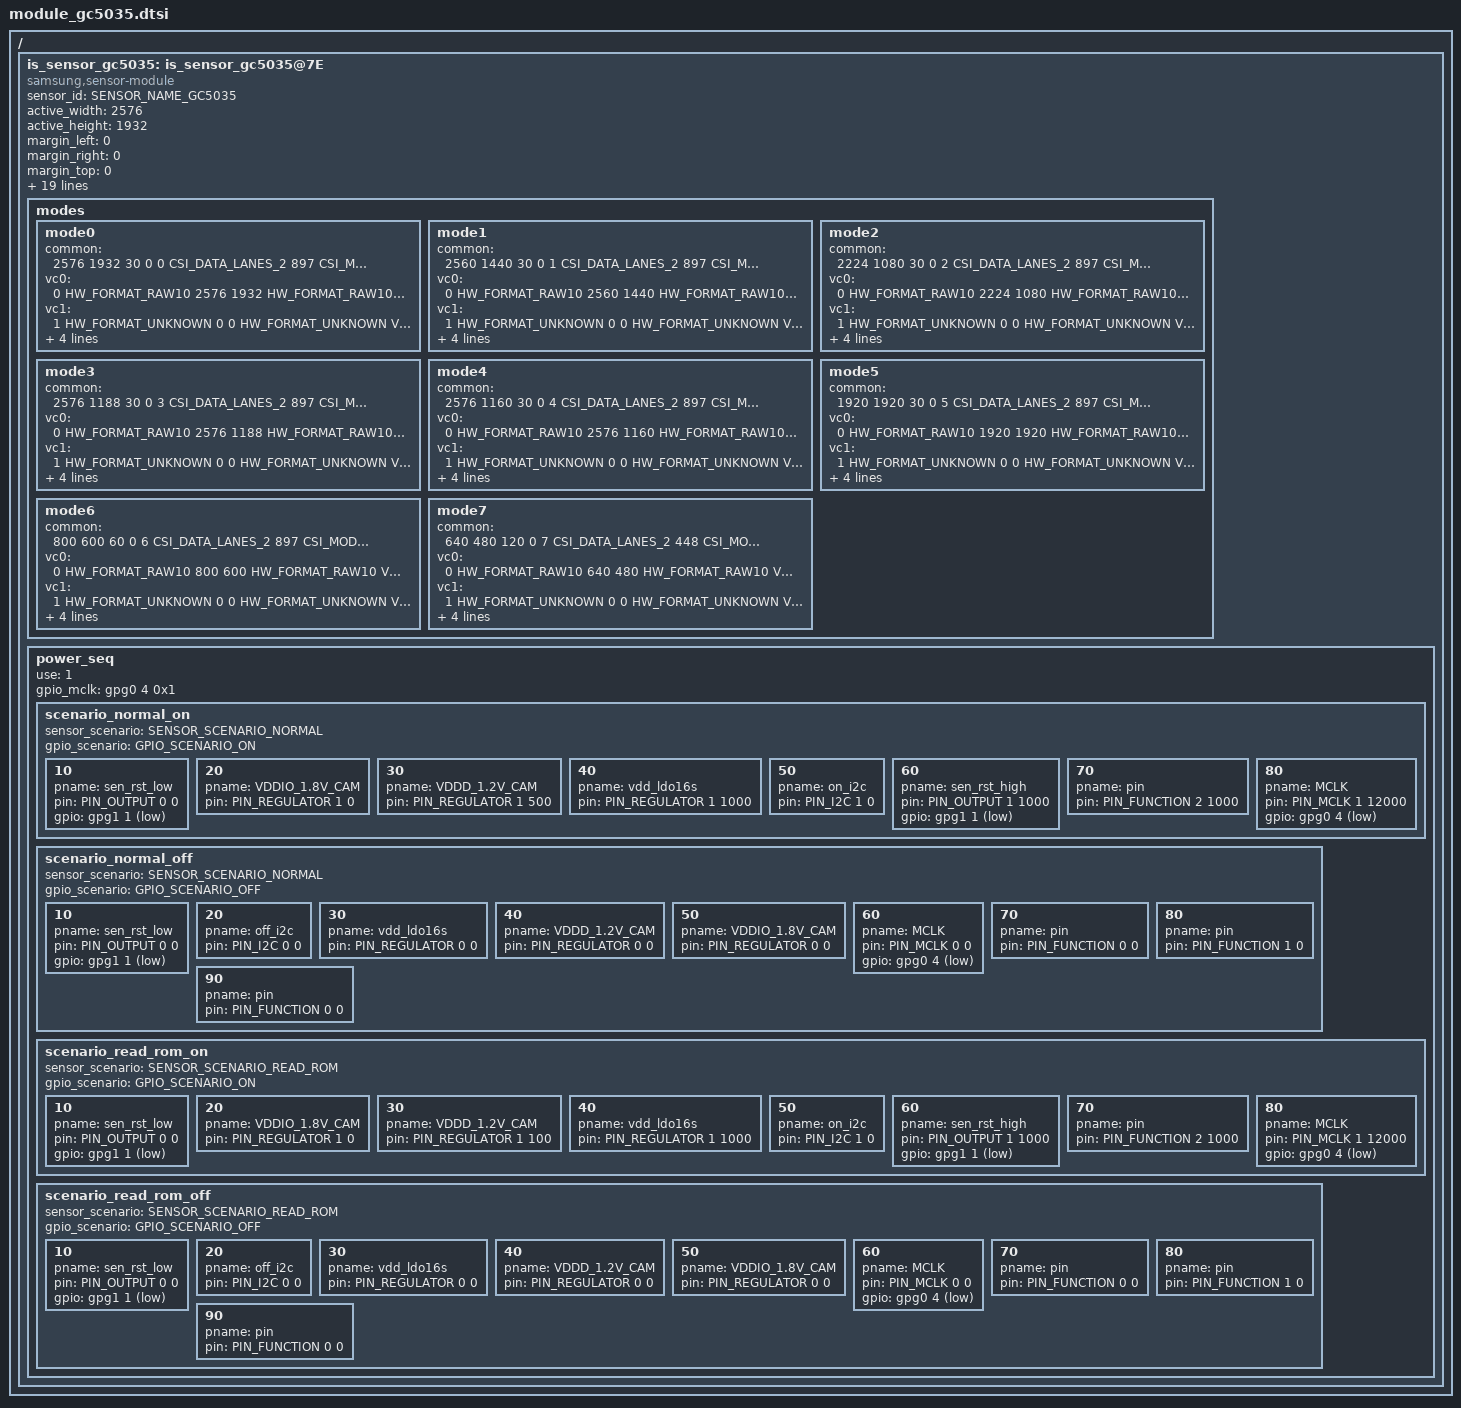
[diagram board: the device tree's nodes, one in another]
/*
 * SAMSUNG EXYNOSxxxx board camera device tree source
 *
 * Copyright (c) 2021 Samsung Electronics Co., Ltd.
 *		http://www.samsung.com
 *
 * This program is free software; you can redistribute it and/or modify
 * it under the terms of the GNU General Public License version 2 as
 * published by the Free Software Foundation.
 */

#include <dt-bindings/camera/exynos_is_dt.h>


/ {
	fragment@camera {
		target-path = "/";
		__overlay__ {
			is_sensor_gc5035: is_sensor_gc5035@7E { /* UW */
				compatible = "samsung,sensor-module";

				/* common */
				sensor_id = <SENSOR_NAME_GC5035>;
				active_width = <2576>;
				active_height = <1932>;
				margin_left = <0>;
				margin_right = <0>;
				margin_top = <0>;
				margin_bottom = <0>;
				max_framerate = <120>;
				bitwidth = <10>;
				use_retention_mode = <SENSOR_RETENTION_UNSUPPORTED>;
				sensor_maker = "GALAXYCORE";
				sensor_name = "GC5035";
				setfile_name = "setfile_gc5035.bin";

				status = "okay";

				/* board */
				pinctrl-names = "pin0", "pin1", "pin2", "release";
				pinctrl-0 = <>;
				pinctrl-1 = <&sensor_mclk2_out>;
				pinctrl-2 = <&sensor_mclk2_fn>;
				pinctrl-3 = <>;

				position = <4>; /* Rear:0. Front:1, Tele:2 */
				id = <4>; /* is_sensor id */
				mclk_ch = <2>;
				sensor_i2c_ch = <1>; /* SENSOR_CONTROL_I2C3 */

				/* vendor */
				rom_type = <3>; /* ROM_TYPE_OTPROM */
				rom_id = <4>;
				rom_cal_index = <0>;

				/*
				* Reference File : GC5035 MIPI data rate 897M official setfile V1.0.8.xlsx
				*
				*  [ 0 ] 2576 x 1932(4:3)    @30,  MIPI lane: 2, MIPI data rate(Mbps/lane):  897, Mclk(Mhz): 26
				*  [ 1 ] 2560 x 1440(16:9)   @30,  MIPI lane: 2, MIPI data rate(Mbps/lane):  897, Mclk(Mhz): 26
				*  [ 2 ] 2224 x 1080(18.5:9) @30,  MIPI lane: 2, MIPI data rate(Mbps/lane):  897, Mclk(Mhz): 26
				*  [ 3 ] 2576 x 1188(19.5:9) @30,  MIPI lane: 2, MIPI data rate(Mbps/lane):  897, Mclk(Mhz): 26
				*  [ 4 ] 2576 x 1160(20:9)   @30,  MIPI lane: 2, MIPI data rate(Mbps/lane):  897, Mclk(Mhz): 26
				*  [ 5 ] 1920 x 1920(1:1)    @30,  MIPI lane: 2, MIPI data rate(Mbps/lane):  897, Mclk(Mhz): 26
				*  [ 6 ] 1280 x 960(4:3)     @30,  MIPI lane: 2, MIPI data rate(Mbps/lane):  897, Mclk(Mhz): 26
				*  [ 7 ] 1280 x 720(16:9)    @30,  MIPI lane: 2, MIPI data rate(Mbps/lane):  897, Mclk(Mhz): 26
				*  [ 8 ] 800 x 600(4:3)      @60,  MIPI lane: 2, MIPI data rate(Mbps/lane):  897, Mclk(Mhz): 26
				*  [ 9 ] 640 x 480(4:3)      @120,  MIPI lane: 2, MIPI data rate(Mbps/lane):  448, Mclk(Mhz): 26
				*/

				/* sensor modes */
				modes {
						/* common = <width, height, fps, settle, mode, lane, speed, interleave, lrte, pd_mode> */
						/* vcX = <map, hwformat, width, height, hwformat, type, width, height> */

					/* 0 : 2576x1932@30fps 4:3 */
					mode0 {
						common = <2576 1932 30 0 0 CSI_DATA_LANES_2 897 CSI_MODE_VC_ONLY LRTE_DISABLE PD_NONE EX_NONE>;
						vc0 = </* in */ 0 HW_FORMAT_RAW10 2576 1932	/* out */ HW_FORMAT_RAW10 VC_NOTHING 0 0>;
						vc1 = </* in */ 1 HW_FORMAT_UNKNOWN 0 0		/* out */ HW_FORMAT_UNKNOWN VC_NOTHING 0 0>;
						vc2 = </* in */ 2 HW_FORMAT_UNKNOWN 0 0		/* out */ HW_FORMAT_UNKNOWN VC_NOTHING 0 0>;
						vc3 = </* in */ 3 HW_FORMAT_UNKNOWN 0 0		/* out */ HW_FORMAT_UNKNOWN VC_NOTHING 0 0>;
					};
					mode1 {
						common = <2560 1440 30 0 1 CSI_DATA_LANES_2 897 CSI_MODE_VC_ONLY LRTE_DISABLE PD_NONE EX_NONE>;
						vc0 = </* in */ 0 HW_FORMAT_RAW10 2560 1440	/* out */ HW_FORMAT_RAW10 VC_NOTHING 0 0>;
						vc1 = </* in */ 1 HW_FORMAT_UNKNOWN 0 0		/* out */ HW_FORMAT_UNKNOWN VC_NOTHING 0 0>;
						vc2 = </* in */ 2 HW_FORMAT_UNKNOWN 0 0		/* out */ HW_FORMAT_UNKNOWN VC_NOTHING 0 0>;
						vc3 = </* in */ 3 HW_FORMAT_UNKNOWN 0 0		/* out */ HW_FORMAT_UNKNOWN VC_NOTHING 0 0>;
					};
					mode2 {
						common = <2224 1080 30 0 2 CSI_DATA_LANES_2 897 CSI_MODE_VC_ONLY LRTE_DISABLE PD_NONE EX_NONE>;
						vc0 = </* in */ 0 HW_FORMAT_RAW10 2224 1080	/* out */ HW_FORMAT_RAW10 VC_NOTHING 0 0>;
						vc1 = </* in */ 1 HW_FORMAT_UNKNOWN 0 0		/* out */ HW_FORMAT_UNKNOWN VC_NOTHING 0 0>;
						vc2 = </* in */ 2 HW_FORMAT_UNKNOWN 0 0		/* out */ HW_FORMAT_UNKNOWN VC_NOTHING 0 0>;
						vc3 = </* in */ 3 HW_FORMAT_UNKNOWN 0 0		/* out */ HW_FORMAT_UNKNOWN VC_NOTHING 0 0>;
					};
					mode3 {
						common = <2576 1188 30 0 3 CSI_DATA_LANES_2 897 CSI_MODE_VC_ONLY LRTE_DISABLE PD_NONE EX_NONE>;
						vc0 = </* in */ 0 HW_FORMAT_RAW10 2576 1188	/* out */ HW_FORMAT_RAW10 VC_NOTHING 0 0>;
						vc1 = </* in */ 1 HW_FORMAT_UNKNOWN 0 0		/* out */ HW_FORMAT_UNKNOWN VC_NOTHING 0 0>;
						vc2 = </* in */ 2 HW_FORMAT_UNKNOWN 0 0		/* out */ HW_FORMAT_UNKNOWN VC_NOTHING 0 0>;
						vc3 = </* in */ 3 HW_FORMAT_UNKNOWN 0 0		/* out */ HW_FORMAT_UNKNOWN VC_NOTHING 0 0>;
					};
					mode4 {
						common = <2576 1160 30 0 4 CSI_DATA_LANES_2 897 CSI_MODE_VC_ONLY LRTE_DISABLE PD_NONE EX_NONE>;
						vc0 = </* in */ 0 HW_FORMAT_RAW10 2576 1160	/* out */ HW_FORMAT_RAW10 VC_NOTHING 0 0>;
						vc1 = </* in */ 1 HW_FORMAT_UNKNOWN 0 0		/* out */ HW_FORMAT_UNKNOWN VC_NOTHING 0 0>;
						vc2 = </* in */ 2 HW_FORMAT_UNKNOWN 0 0		/* out */ HW_FORMAT_UNKNOWN VC_NOTHING 0 0>;
						vc3 = </* in */ 3 HW_FORMAT_UNKNOWN 0 0		/* out */ HW_FORMAT_UNKNOWN VC_NOTHING 0 0>;
					};
					mode5 {
						common = <1920 1920 30 0 5 CSI_DATA_LANES_2 897 CSI_MODE_VC_ONLY LRTE_DISABLE PD_NONE EX_NONE>;
						vc0 = </* in */ 0 HW_FORMAT_RAW10 1920 1920	/* out */ HW_FORMAT_RAW10 VC_NOTHING 0 0>;
						vc1 = </* in */ 1 HW_FORMAT_UNKNOWN 0 0		/* out */ HW_FORMAT_UNKNOWN VC_NOTHING 0 0>;
						vc2 = </* in */ 2 HW_FORMAT_UNKNOWN 0 0		/* out */ HW_FORMAT_UNKNOWN VC_NOTHING 0 0>;
						vc3 = </* in */ 3 HW_FORMAT_UNKNOWN 0 0		/* out */ HW_FORMAT_UNKNOWN VC_NOTHING 0 0>;
					};
					/* 6 : 800x600@60fps 4:3 */
					mode6 {
						common = <800 600 60 0 6 CSI_DATA_LANES_2 897 CSI_MODE_VC_ONLY LRTE_DISABLE PD_NONE EX_NONE>;
						vc0 = </* in */ 0 HW_FORMAT_RAW10 800 600	/* out */ HW_FORMAT_RAW10 VC_NOTHING 0 0>;
						vc1 = </* in */ 1 HW_FORMAT_UNKNOWN 0 0		/* out */ HW_FORMAT_UNKNOWN VC_NOTHING 0 0>;
						vc2 = </* in */ 2 HW_FORMAT_UNKNOWN 0 0		/* out */ HW_FORMAT_UNKNOWN VC_NOTHING 0 0>;
						vc3 = </* in */ 3 HW_FORMAT_UNKNOWN 0 0		/* out */ HW_FORMAT_UNKNOWN VC_NOTHING 0 0>;
					};
					/* 7 : 640x480@120fps 4:3 */
					mode7 {
						common = <640 480 120 0 7 CSI_DATA_LANES_2 448 CSI_MODE_VC_ONLY LRTE_DISABLE PD_NONE EX_NONE>;
						vc0 = </* in */ 0 HW_FORMAT_RAW10 640 480	/* out */ HW_FORMAT_RAW10 VC_NOTHING 0 0>;
						vc1 = </* in */ 1 HW_FORMAT_UNKNOWN 0 0		/* out */ HW_FORMAT_UNKNOWN VC_NOTHING 0 0>;
						vc2 = </* in */ 2 HW_FORMAT_UNKNOWN 0 0		/* out */ HW_FORMAT_UNKNOWN VC_NOTHING 0 0>;
						vc3 = </* in */ 3 HW_FORMAT_UNKNOWN 0 0		/* out */ HW_FORMAT_UNKNOWN VC_NOTHING 0 0>;
					};
				};

				power_seq {
					use = <1>;
					gpio_mclk = <&gpg0 4 0x1>;
					scenario_normal_on {
						sensor_scenario = <SENSOR_SCENARIO_NORMAL>;
						gpio_scenario = <GPIO_SCENARIO_ON>;

						/* A start node number should be over the 10 for reserved number 0~9. */
						/* pname = "name"; pin = <act value delay voltage>; gpio = <gpx# # 0x1>; */
						10 { pname = "sen_rst_low"; pin = <PIN_OUTPUT 0 0>; gpio = <&gpg1 1 0x1>; };
						20 { pname = "VDDIO_1.8V_CAM"; pin = <PIN_REGULATOR 1 0>; };
						30 { pname = "VDDD_1.2V_CAM"; pin = <PIN_REGULATOR 1 500>; };
						40 { pname = "vdd_ldo16s"; pin = <PIN_REGULATOR 1 1000>; };
						50 { pname = "on_i2c"; pin = <PIN_I2C 1 0>; };
						60 { pname = "sen_rst_high"; pin = <PIN_OUTPUT 1 1000>; gpio = <&gpg1 1 0x1>; };
						70 { pname = "pin"; pin = <PIN_FUNCTION 2 1000>; };
						80 { pname = "MCLK"; pin = <PIN_MCLK 1 12000>; gpio = <&gpg0 4 0x1>; };
					};

					scenario_normal_off {
						sensor_scenario = <SENSOR_SCENARIO_NORMAL>;
						gpio_scenario = <GPIO_SCENARIO_OFF>;
						/* A start node number should be over the 10 for reserved number 0~9. */
						/* pname = "name"; pin = <act value delay voltage>; gpio = <gpx# # 0x1>; */
						10 { pname = "sen_rst_low"; pin = <PIN_OUTPUT 0 0>; gpio = <&gpg1 1 0x1>; };
						20 { pname = "off_i2c"; pin = <PIN_I2C 0 0>; };
						30 { pname = "vdd_ldo16s"; pin = <PIN_REGULATOR 0 0>; };
						40 { pname = "VDDD_1.2V_CAM"; pin = <PIN_REGULATOR 0 0>; };
						50 { pname = "VDDIO_1.8V_CAM"; pin = <PIN_REGULATOR 0 0>; };
						60 { pname = "MCLK"; pin = <PIN_MCLK 0 0>; gpio = <&gpg0 4 0x1>; };
						70 { pname = "pin"; pin = <PIN_FUNCTION 0 0>; };
						80 { pname = "pin"; pin = <PIN_FUNCTION 1 0>; };
						90 { pname = "pin"; pin = <PIN_FUNCTION 0 0>; };
					};

					scenario_read_rom_on {
						sensor_scenario = <SENSOR_SCENARIO_READ_ROM>;
						gpio_scenario = <GPIO_SCENARIO_ON>;
						/* pname = "name"; pin = <act value delay voltage>; gpio = <gpx# # 0x1>; */
						10 { pname = "sen_rst_low"; pin = <PIN_OUTPUT 0 0>; gpio = <&gpg1 1 0x1>; };
						20 { pname = "VDDIO_1.8V_CAM"; pin = <PIN_REGULATOR 1 0>; };
						30 { pname = "VDDD_1.2V_CAM"; pin = <PIN_REGULATOR 1 100>; };
						40 { pname = "vdd_ldo16s"; pin = <PIN_REGULATOR 1 1000>; };
						50 { pname = "on_i2c"; pin = <PIN_I2C 1 0>; };
						60 { pname = "sen_rst_high"; pin = <PIN_OUTPUT 1 1000>; gpio = <&gpg1 1 0x1>; };
						70 { pname = "pin"; pin = <PIN_FUNCTION 2 1000>; };
						80 { pname = "MCLK"; pin = <PIN_MCLK 1 12000>; gpio = <&gpg0 4 0x1>; };
					};

					scenario_read_rom_off {
						sensor_scenario = <SENSOR_SCENARIO_READ_ROM>;
						gpio_scenario = <GPIO_SCENARIO_OFF>;
						/* pname = "name"; pin = <act value delay voltage>; gpio = <gpx# # 0x1>; */
						10 { pname = "sen_rst_low"; pin = <PIN_OUTPUT 0 0>; gpio = <&gpg1 1 0x1>; };
						20 { pname = "off_i2c"; pin = <PIN_I2C 0 0>; };
						30 { pname = "vdd_ldo16s"; pin = <PIN_REGULATOR 0 0>; };
						40 { pname = "VDDD_1.2V_CAM"; pin = <PIN_REGULATOR 0 0>; };
						50 { pname = "VDDIO_1.8V_CAM"; pin = <PIN_REGULATOR 0 0>; };
						60 { pname = "MCLK"; pin = <PIN_MCLK 0 0>; gpio = <&gpg0 4 0x1>; };
						70 { pname = "pin"; pin = <PIN_FUNCTION 0 0>; };
						80 { pname = "pin"; pin = <PIN_FUNCTION 1 0>; };
						90 { pname = "pin"; pin = <PIN_FUNCTION 0 0>; };
					};

				};
			};
		}; /* end of __overlay__ */

	}; /* end of fragment */
}; /* end of root */
